AUTOSAR XML (schema 4-3-0)
package /App_CAN_RX
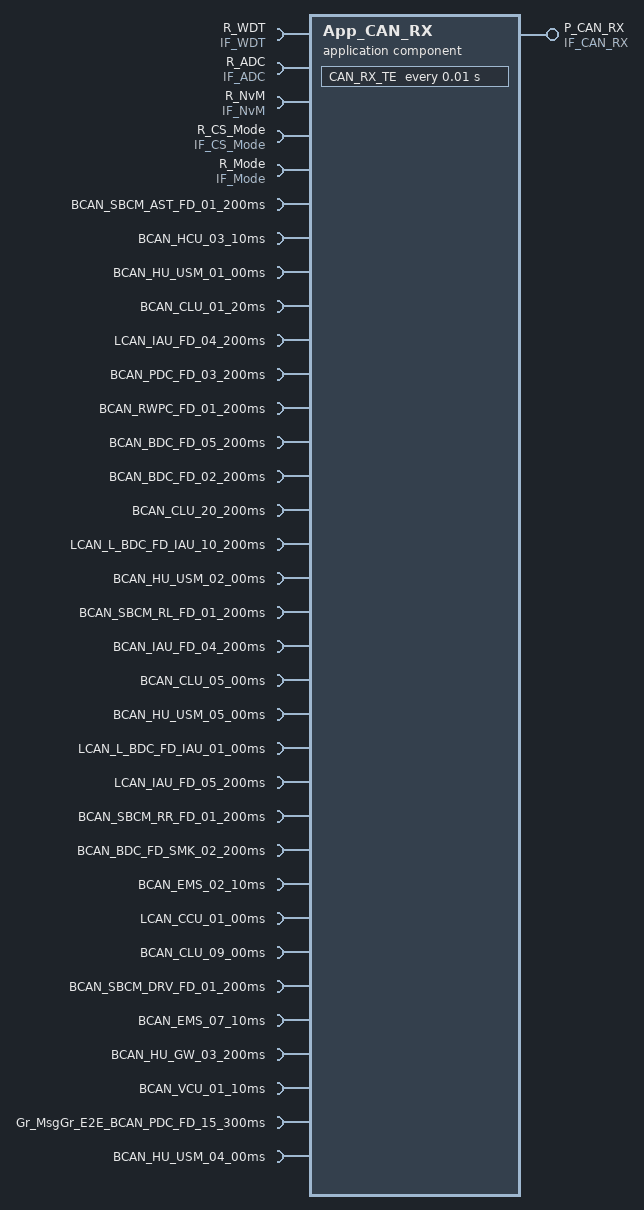
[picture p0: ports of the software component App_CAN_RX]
  application sw component type App_CAN_RX
    5 x require port:
      R_WDT: nonqueued-receiver-com-spec=WDT_STR, required-interface=IF_WDT
      R_ADC: nonqueued-receiver-com-spec=ADC_STR, required-interface=IF_ADC
      R_NvM: nonqueued-receiver-com-spec=NvM_STR, required-interface=IF_NvM
      R_CS_Mode: required-com-specs=[ModeInit, NvMInit, ApplicationInit], required-interface=IF_CS_Mode
      R_Mode: nonqueued-receiver-com-spec=Mode_STR, required-interface=IF_Mode
    provide port P_CAN_RX: nonqueued-sender-com-spec=CAN_RX_STR, provided-interface=IF_CAN_RX
    29 x require port:
      BCAN_SBCM_AST_FD_01_200ms: nonqueued-receiver-com-spec{data-element=Warn_AsstDrSwSta_SBCM, network-representation=compu-method=ISignal_BCAN_SBCM_AST_FD_01_200ms_Warn_AsstDrSwSta_SBCM}, required-interface=BCAN_SBCM_AST_FD_01_200ms
      BCAN_HCU_03_10ms: nonqueued-receiver-com-spec{data-element=HCU_HevRdySta, network-representation=compu-method=ISignal_BCAN_HCU_03_10ms_HCU_HevRdySta}, required-interface=BCAN_HCU_03_10ms
      BCAN_HU_USM_01_00ms: nonqueued-receiver-com-spec{data-element=CF_Gway_WPCNValueSet, network-representation=compu-method=ISignal_BCAN_HU_USM_01_00ms_CF_Gway_WPCNValueSet}, required-interface=BCAN_HU_USM_01_00ms
      BCAN_CLU_01_20ms: required-interface=BCAN_CLU_01_20ms
        required-com-specs:
          data-element=CLU_AutoBrightSta, network-representation=compu-method=ISignal_BCAN_CLU_01_20ms_CLU_AutoBrightSta
          data-element=CLU_DtntOutSta, network-representation=compu-method=ISignal_BCAN_CLU_01_20ms_CLU_DtntOutSta
          data-element=CLU_DisSpdVal_KPH, network-representation=compu-method=ISignal_BCAN_CLU_01_20ms_CLU_DisSpdVal_KPH, alive-timeout=1.5, handle-timeout-type=REPLACE-BY-TIMEOUT-SUBSTITUTION-VALUE, timeout-substitution-value=255
          data-element=CLU_RhstaLvlSta, network-representation=compu-method=ISignal_BCAN_CLU_01_20ms_CLU_RhstaLvlSta, alive-timeout=1.5, handle-timeout-type=REPLACE-BY-TIMEOUT-SUBSTITUTION-VALUE, timeout-substitution-value=10
      LCAN_IAU_FD_04_200ms: required-interface=LCAN_IAU_FD_04_200ms
        required-com-specs:
          data-element=IAU_OwnerPhnRegRVal, network-representation=compu-method=ISignal_LCAN_IAU_FD_04_200ms_IAU_OwnerPhnRegRVal
          data-element=IAU_DKOwnerSwapOption, network-representation=compu-method=ISignal_LCAN_IAU_FD_04_200ms_IAU_DKOwnerSwapOption
      BCAN_PDC_FD_03_200ms: required-interface=BCAN_PDC_FD_03_200ms
        required-com-specs:
          data-element=Warn_RrRtDrSwSta, network-representation=compu-method=ISignal_BCAN_PDC_FD_03_200ms_Warn_RrRtDrSwSta
          data-element=Warn_AsstDrSwSta, network-representation=compu-method=ISignal_BCAN_PDC_FD_03_200ms_Warn_AsstDrSwSta
          data-element=Warn_DrvDrSwSta, network-representation=compu-method=ISignal_BCAN_PDC_FD_03_200ms_Warn_DrvDrSwSta
          data-element=Warn_RrLftDrSwSta, network-representation=compu-method=ISignal_BCAN_PDC_FD_03_200ms_Warn_RrLftDrSwSta
      BCAN_RWPC_FD_01_200ms: nonqueued-receiver-com-spec{data-element=RWPC_IndSyncVal, network-representation=compu-method=ISignal_BCAN_RWPC_FD_01_200ms_RWPC_IndSyncVal}, required-interface=BCAN_RWPC_FD_01_200ms
      BCAN_BDC_FD_05_200ms: nonqueued-receiver-com-spec{data-element=Lamp_IntTailLmpOnReq, network-representation=compu-method=ISignal_BCAN_BDC_FD_05_200ms_Lamp_IntTailLmpOnReq}, required-interface=BCAN_BDC_FD_05_200ms
      BCAN_BDC_FD_02_200ms: nonqueued-receiver-com-spec{data-element=BCM_SmkOptTyp, network-representation=compu-method=ISignal_BCAN_BDC_FD_02_200ms_BCM_SmkOptTyp}, required-interface=BCAN_BDC_FD_02_200ms
      BCAN_CLU_20_200ms: nonqueued-receiver-com-spec{data-element=CLU_ClusterUSM, network-representation=compu-method=ISignal_BCAN_CLU_20_200ms_CLU_ClusterUSM}, required-interface=BCAN_CLU_20_200ms
      LCAN_L_BDC_FD_IAU_10_200ms: required-interface=LCAN_L_BDC_FD_IAU_10_200ms
        required-com-specs:
          data-element=OPAdv_On_Cmd, network-representation=compu-method=ISignal_LCAN_L_BDC_FD_IAU_10_200ms_OPAdv_On_Cmd
          data-element=BDC_TP_CAN_Sta, network-representation=compu-method=ISignal_LCAN_L_BDC_FD_IAU_10_200ms_BDC_TP_CAN_Sta
          data-element=WPC_Device_On_Cmd, network-representation=compu-method=ISignal_LCAN_L_BDC_FD_IAU_10_200ms_WPC_Device_On_Cmd
      BCAN_HU_USM_02_00ms: nonqueued-receiver-com-spec{data-element=CF_AVN_CluUSMReset, network-representation=compu-method=ISignal_BCAN_HU_USM_02_00ms_CF_AVN_CluUSMReset}, required-interface=BCAN_HU_USM_02_00ms
      BCAN_SBCM_RL_FD_01_200ms: nonqueued-receiver-com-spec{data-element=Warn_RrLftDrSwSta_SBCM, network-representation=compu-method=ISignal_BCAN_SBCM_RL_FD_01_200ms_Warn_RrLftDrSwSta_SBCM}, required-interface=BCAN_SBCM_RL_FD_01_200ms
      BCAN_IAU_FD_04_200ms: required-interface=BCAN_IAU_FD_04_200ms
        required-com-specs:
          data-element=IAU_ProfileIDRVal, network-representation=compu-method=ISignal_BCAN_IAU_FD_04_200ms_IAU_ProfileIDRVal
          data-element=IAU_DigitalKey2Opt, network-representation=compu-method=ISignal_BCAN_IAU_FD_04_200ms_IAU_DigitalKey2Opt
      BCAN_CLU_05_00ms: nonqueued-receiver-com-spec{data-element=USM_StaRst1Req, network-representation=compu-method=ISignal_BCAN_CLU_05_00ms_USM_StaRst1Req}, required-interface=BCAN_CLU_05_00ms
      BCAN_HU_USM_05_00ms: nonqueued-receiver-com-spec{data-element=CF_Gway_WPCAnimationNvalueSet, network-representation=compu-method=ISignal_BCAN_HU_USM_05_00ms_CF_Gway_WPCAnimationNvalueSet}, required-interface=BCAN_HU_USM_05_00ms
      LCAN_L_BDC_FD_IAU_01_00ms: required-interface=LCAN_L_BDC_FD_IAU_01_00ms
        required-com-specs:
          data-element=WPC_NFC_Deselect_Cmd, network-representation=compu-method=ISignal_LCAN_L_BDC_FD_IAU_01_00ms_WPC_NFC_Deselect_Cmd
          data-element=WPC2_NFC_Deselect_Cmd, network-representation=compu-method=ISignal_LCAN_L_BDC_FD_IAU_01_00ms_WPC2_NFC_Deselect_Cmd
      LCAN_IAU_FD_05_200ms: nonqueued-receiver-com-spec{data-element=IAU_SharedPhnRegStat, network-representation=compu-method=ISignal_LCAN_IAU_FD_05_200ms_IAU_SharedPhnRegStat}, required-interface=LCAN_IAU_FD_05_200ms
      BCAN_SBCM_RR_FD_01_200ms: nonqueued-receiver-com-spec{data-element=Warn_RrRtDrSwSta_SBCM, network-representation=compu-method=ISignal_BCAN_SBCM_RR_FD_01_200ms_Warn_RrRtDrSwSta_SBCM}, required-interface=BCAN_SBCM_RR_FD_01_200ms
      BCAN_BDC_FD_SMK_02_200ms: nonqueued-receiver-com-spec{data-element=LFAnt_SrchSta, network-representation=compu-method=ISignal_BCAN_BDC_FD_SMK_02_200ms_LFAnt_SrchSta}, required-interface=BCAN_BDC_FD_SMK_02_200ms
      BCAN_EMS_02_10ms: nonqueued-receiver-com-spec{data-element=ENG_EngSta, network-representation=compu-method=ISignal_BCAN_EMS_02_10ms_ENG_EngSta}, required-interface=BCAN_EMS_02_10ms
      LCAN_CCU_01_00ms: nonqueued-receiver-com-spec{data-element=CCU_ForcedPowerOffReq, network-representation=compu-method=ISignal_LCAN_CCU_01_00ms_CCU_ForcedPowerOffReq}, required-interface=LCAN_CCU_01_00ms
      BCAN_CLU_09_00ms: required-interface=BCAN_CLU_09_00ms
        required-com-specs:
          data-element=USM_WpcSetReq, network-representation=compu-method=ISignal_BCAN_CLU_09_00ms_USM_WpcSetReq
          data-element=USM_Wpc2SetReq, network-representation=compu-method=ISignal_BCAN_CLU_09_00ms_USM_Wpc2SetReq
      BCAN_SBCM_DRV_FD_01_200ms: required-interface=BCAN_SBCM_DRV_FD_01_200ms
        required-com-specs:
          data-element=Latch_TypeOption_DRV, network-representation=compu-method=ISignal_BCAN_SBCM_DRV_FD_01_200ms_Latch_TypeOption_DRV
          data-element=Warn_DrvDrSwSta_SBCM, network-representation=compu-method=ISignal_BCAN_SBCM_DRV_FD_01_200ms_Warn_DrvDrSwSta_SBCM
      BCAN_EMS_07_10ms: nonqueued-receiver-com-spec{data-element=HEV_EngOpSta, network-representation=compu-method=ISignal_BCAN_EMS_07_10ms_HEV_EngOpSta, alive-timeout=0.5, handle-timeout-type=REPLACE-BY-TIMEOUT-SUBSTITUTION-VALUE, timeout-substitution-value=7}, required-interface=BCAN_EMS_07_10ms
      BCAN_HU_GW_03_200ms: nonqueued-receiver-com-spec{data-element=CF_AVN_ProfileIDRValue, network-representation=compu-method=ISignal_BCAN_HU_GW_03_200ms_CF_AVN_ProfileIDRValue}, required-interface=BCAN_HU_GW_03_200ms
      BCAN_VCU_01_10ms: nonqueued-receiver-com-spec{data-element=VCU_EvDrvRdySta, network-representation=compu-method=ISignal_BCAN_VCU_01_10ms_VCU_EvDrvRdySta}, required-interface=BCAN_VCU_01_10ms
      Gr_MsgGr_E2E_BCAN_PDC_FD_15_300ms: nonqueued-receiver-com-spec=data-element=MsgGr_E2E_BCAN_PDC_FD_15_300ms, required-interface=Gr_MsgGr_E2E_BCAN_PDC_FD_15_300ms
      BCAN_HU_USM_04_00ms: nonqueued-receiver-com-spec{data-element=CF_Gway_WPC2_NValueSet, network-representation=compu-method=ISignal_BCAN_HU_USM_04_00ms_CF_Gway_WPC2_NValueSet}, required-interface=BCAN_HU_USM_04_00ms
    behavior InternalBehavior: data-type-mapping=DataTypeMappingSet_WPC
      timing event TE_CAN_RX_TE: start-on-event=CAN_RX_TE, period=0.01
      data receive error event DREE_DREE_CLU_01_20ms_2_BCAN_CLU_01_20ms_CLU_DisSpdVal_KPH: start-on-event=DREE_DisSpdVal_KPH, data=BCAN_CLU_01_20ms.CLU_DisSpdVal_KPH
      data receive error event DREE_DREE_CLU_01_20ms_1_BCAN_CLU_01_20ms_CLU_RhstaLvlSta: start-on-event=DREE_RhstaLvlSta, data=BCAN_CLU_01_20ms.CLU_RhstaLvlSta
      data receive error event DREE_DREE_HEV_EngOpSta_BCAN_EMS_07_10ms_HEV_EngOpSta: start-on-event=DREE_HEV_EngOpSta, data=BCAN_EMS_07_10ms.HEV_EngOpSta
      data received event DRE_DRE_PDC_FD_15_300ms_Gr_MsgGr_E2E_BCAN_PDC_FD_15_300ms_MsgGr_E2E_BCAN_PDC_FD_15_300ms: start-on-event=DRE_PDC_FD_15_300ms, data=Gr_MsgGr_E2E_BCAN_PDC_FD_15_300ms.MsgGr_E2E_BCAN_PDC_FD_15_300ms
      5 x runnable:
        CAN_RX_TE: symbol=CAN_RX_TE_Runnable
          data-receive-point-by-arguments:
            5 x access, all with scope=COMMUNICATION-INTER-ECU:
              DRPBA_BCAN_RX_TE_R_ADC_Structure: accessed-variable=R_ADC.ADC_STR
              DRPBA_BCAN_RX_TE_R_Mode_Structure: accessed-variable=R_Mode.Mode_STR
              DRPBA_BCAN_RX_TE_R_NvM_Structure: accessed-variable=R_NvM.NvM_STR
              DRPBA_CAN_RX_TE_Gr_MsgGr_E2E_BCAN_PDC_FD_15_300ms_MsgGr_E2E_BCAN_PDC_FD_15_300ms: accessed-variable=Gr_MsgGr_E2E_BCAN_PDC_FD_15_300ms.MsgGr_E2E_BCAN_PDC_FD_15_300ms
              DRPBA_CAN_RX_TE_R_WDT_WDT_STR: accessed-variable=R_WDT.WDT_STR
          data-receive-point-by-values:
            41 x access, all with scope=COMMUNICATION-INTER-ECU:
              DRPBV_CAN_RX_TE_BCAN_HCU_03_10ms_HCU_HevRdySta: accessed-variable=BCAN_HCU_03_10ms.HCU_HevRdySta
              DRPBV_CAN_RX_TE_BCAN_CLU_01_20ms_CLU_AutoBrightSta: accessed-variable=BCAN_CLU_01_20ms.CLU_AutoBrightSta
              DRPBV_CAN_RX_TE_BCAN_CLU_01_20ms_CLU_DtntOutSta: accessed-variable=BCAN_CLU_01_20ms.CLU_DtntOutSta
              DRPBV_CAN_RX_TE_BCAN_CLU_01_20ms_CLU_DisSpdVal_KPH: accessed-variable=BCAN_CLU_01_20ms.CLU_DisSpdVal_KPH
              DRPBV_CAN_RX_TE_BCAN_CLU_20_200ms_CLU_ClusterUSM: accessed-variable=BCAN_CLU_20_200ms.CLU_ClusterUSM
              DRPBV_CAN_RX_TE_LCAN_L_BDC_FD_IAU_10_200ms_OPAdv_On_Cmd: accessed-variable=LCAN_L_BDC_FD_IAU_10_200ms.OPAdv_On_Cmd
              DRPBV_CAN_RX_TE_BCAN_CLU_05_00ms_USM_StaRst1Req: accessed-variable=BCAN_CLU_05_00ms.USM_StaRst1Req
              DRPBV_CAN_RX_TE_BCAN_CLU_01_20ms_CLU_RhstaLvlSta: accessed-variable=BCAN_CLU_01_20ms.CLU_RhstaLvlSta
              DRPBV_CAN_RX_TE_LCAN_L_BDC_FD_IAU_10_200ms_BDC_TP_CAN_Sta: accessed-variable=LCAN_L_BDC_FD_IAU_10_200ms.BDC_TP_CAN_Sta
              DRPBV_CAN_RX_TE_LCAN_L_BDC_FD_IAU_01_00ms_WPC_NFC_Deselect_Cmd: accessed-variable=LCAN_L_BDC_FD_IAU_01_00ms.WPC_NFC_Deselect_Cmd
              DRPBV_CAN_RX_TE_LCAN_L_BDC_FD_IAU_10_200ms_WPC_Device_On_Cmd: accessed-variable=LCAN_L_BDC_FD_IAU_10_200ms.WPC_Device_On_Cmd
              DRPBV_CAN_RX_TE_BCAN_EMS_02_10ms_ENG_EngSta: accessed-variable=BCAN_EMS_02_10ms.ENG_EngSta
              DRPBV_CAN_RX_TE_LCAN_CCU_01_00ms_CCU_ForcedPowerOffReq: accessed-variable=LCAN_CCU_01_00ms.CCU_ForcedPowerOffReq
              DRPBV_CAN_RX_TE_BCAN_CLU_09_00ms_USM_WpcSetReq: accessed-variable=BCAN_CLU_09_00ms.USM_WpcSetReq
              DRPBV_CAN_RX_TE_BCAN_EMS_07_10ms_HEV_EngOpSta: accessed-variable=BCAN_EMS_07_10ms.HEV_EngOpSta
              DRPBV_CAN_RX_TE_BCAN_VCU_01_10ms_VCU_EvDrvRdySta: accessed-variable=BCAN_VCU_01_10ms.VCU_EvDrvRdySta
              DRPBV_CAN_RX_TE_LCAN_L_BDC_FD_IAU_01_00ms_WPC2_NFC_Deselect_Cmd: accessed-variable=LCAN_L_BDC_FD_IAU_01_00ms.WPC2_NFC_Deselect_Cmd
              DRPBV_CAN_RX_TE_BCAN_SBCM_AST_FD_01_200ms_Warn_AsstDrSwSta_SBCM: accessed-variable=BCAN_SBCM_AST_FD_01_200ms.Warn_AsstDrSwSta_SBCM
              DRPBV_CAN_RX_TE_BCAN_SBCM_DRV_FD_01_200ms_Latch_TypeOption_DRV: accessed-variable=BCAN_SBCM_DRV_FD_01_200ms.Latch_TypeOption_DRV
              DRPBV_CAN_RX_TE_BCAN_HU_USM_01_00ms_CF_Gway_WPCNValueSet: accessed-variable=BCAN_HU_USM_01_00ms.CF_Gway_WPCNValueSet
              DRPBV_CAN_RX_TE_BCAN_PDC_FD_03_200ms_Warn_RrRtDrSwSta: accessed-variable=BCAN_PDC_FD_03_200ms.Warn_RrRtDrSwSta
              DRPBV_CAN_RX_TE_BCAN_RWPC_FD_01_200ms_RWPC_IndSyncVal: accessed-variable=BCAN_RWPC_FD_01_200ms.RWPC_IndSyncVal
              DRPBV_CAN_RX_TE_BCAN_BDC_FD_05_200ms_Lamp_IntTailLmpOnReq: accessed-variable=BCAN_BDC_FD_05_200ms.Lamp_IntTailLmpOnReq
              DRPBV_CAN_RX_TE_BCAN_BDC_FD_02_200ms_BCM_SmkOptTyp: accessed-variable=BCAN_BDC_FD_02_200ms.BCM_SmkOptTyp
              DRPBV_CAN_RX_TE_BCAN_PDC_FD_03_200ms_Warn_AsstDrSwSta: accessed-variable=BCAN_PDC_FD_03_200ms.Warn_AsstDrSwSta
              DRPBV_CAN_RX_TE_BCAN_PDC_FD_03_200ms_Warn_DrvDrSwSta: accessed-variable=BCAN_PDC_FD_03_200ms.Warn_DrvDrSwSta
              DRPBV_CAN_RX_TE_BCAN_HU_USM_02_00ms_CF_AVN_CluUSMReset: accessed-variable=BCAN_HU_USM_02_00ms.CF_AVN_CluUSMReset
              DRPBV_CAN_RX_TE_BCAN_SBCM_RL_FD_01_200ms_Warn_RrLftDrSwSta_SBCM: accessed-variable=BCAN_SBCM_RL_FD_01_200ms.Warn_RrLftDrSwSta_SBCM
              DRPBV_CAN_RX_TE_BCAN_IAU_FD_04_200ms_IAU_ProfileIDRVal: accessed-variable=BCAN_IAU_FD_04_200ms.IAU_ProfileIDRVal
              DRPBV_CAN_RX_TE_BCAN_HU_USM_05_00ms_CF_Gway_WPCAnimationNvalueSet: accessed-variable=BCAN_HU_USM_05_00ms.CF_Gway_WPCAnimationNvalueSet
              DRPBV_CAN_RX_TE_BCAN_IAU_FD_04_200ms_IAU_DigitalKey2Opt: accessed-variable=BCAN_IAU_FD_04_200ms.IAU_DigitalKey2Opt
              DRPBV_CAN_RX_TE_BCAN_PDC_FD_03_200ms_Warn_RrLftDrSwSta: accessed-variable=BCAN_PDC_FD_03_200ms.Warn_RrLftDrSwSta
              DRPBV_CAN_RX_TE_BCAN_SBCM_RR_FD_01_200ms_Warn_RrRtDrSwSta_SBCM: accessed-variable=BCAN_SBCM_RR_FD_01_200ms.Warn_RrRtDrSwSta_SBCM
              DRPBV_CAN_RX_TE_BCAN_BDC_FD_SMK_02_200ms_LFAnt_SrchSta: accessed-variable=BCAN_BDC_FD_SMK_02_200ms.LFAnt_SrchSta
              DRPBV_CAN_RX_TE_BCAN_SBCM_DRV_FD_01_200ms_Warn_DrvDrSwSta_SBCM: accessed-variable=BCAN_SBCM_DRV_FD_01_200ms.Warn_DrvDrSwSta_SBCM
              DRPBV_CAN_RX_TE_BCAN_HU_GW_03_200ms_CF_AVN_ProfileIDRValue: accessed-variable=BCAN_HU_GW_03_200ms.CF_AVN_ProfileIDRValue
              DRPBV_CAN_RX_TE_BCAN_HU_USM_04_00ms_CF_Gway_WPC2_NValueSet: accessed-variable=BCAN_HU_USM_04_00ms.CF_Gway_WPC2_NValueSet
              DRPBV_CAN_RX_TE_LCAN_IAU_FD_04_200ms_IAU_OwnerPhnRegRVal: accessed-variable=LCAN_IAU_FD_04_200ms.IAU_OwnerPhnRegRVal
              DRPBV_CAN_RX_TE_LCAN_IAU_FD_04_200ms_IAU_DKOwnerSwapOption: accessed-variable=LCAN_IAU_FD_04_200ms.IAU_DKOwnerSwapOption
              DRPBV_CAN_RX_TE_LCAN_IAU_FD_05_200ms_IAU_SharedPhnRegStat: accessed-variable=LCAN_IAU_FD_05_200ms.IAU_SharedPhnRegStat
              DRPBV_CAN_RX_TE_BCAN_CLU_09_00ms_USM_Wpc2SetReq: accessed-variable=BCAN_CLU_09_00ms.USM_Wpc2SetReq
          data-send-points:
            access DSP_BCAN_RX_TE_P_BCAN_RX_BCAN_RX_u8_arr: accessed-variable=P_CAN_RX.CAN_RX_STR, scope=COMMUNICATION-INTER-ECU
          sync call SSCP_BCAN_RX_TE_R_CS_Mode_ApplicationInit: operation=R_CS_Mode.ApplicationInit
          sync call SSCP_BCAN_RX_TE_R_CS_Mode_ModeInit: operation=R_CS_Mode.ModeInit
          sync call SSCP_BCAN_RX_TE_R_CS_Mode_NvMInit: operation=R_CS_Mode.NvMInit
        DREE_RhstaLvlSta: symbol=DREE_RhstaLvlSta_Runnable
        DREE_DisSpdVal_KPH: symbol=DREE_DisSpdVal_KPH_Runnable
        DREE_HEV_EngOpSta: symbol=DREE_HEV_EngOpSta_Runnable
        DRE_PDC_FD_15_300ms: symbol=DRE_PDC_FD_15_300ms_Runnable
  sender receiver interface IF_CAN_RX  # NFC SWC Output
    data CAN_RX_STR: type=IDT_CAN_RX_STR
